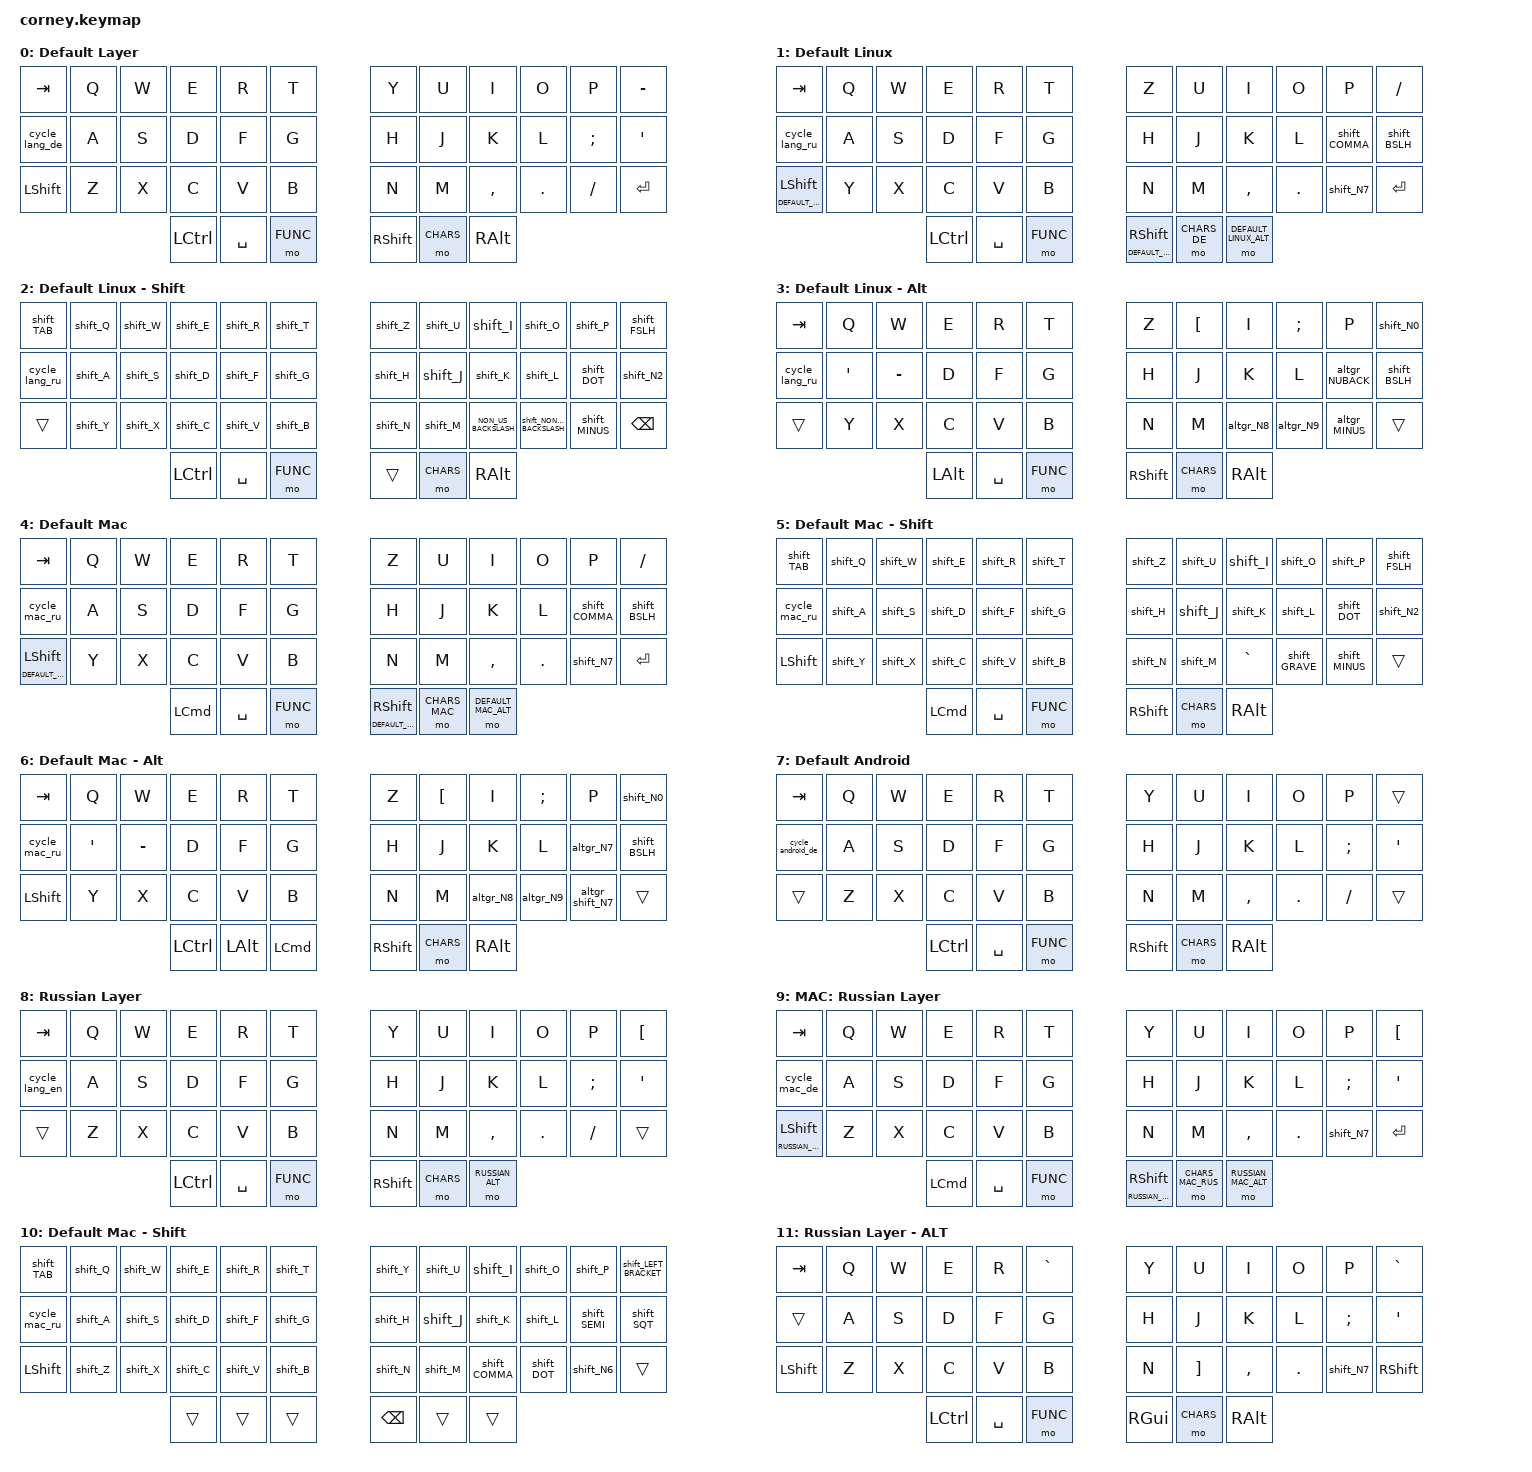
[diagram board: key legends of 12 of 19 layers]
/*
 * Copyright (c) 2020 The ZMK Contributors
 *
 * SPDX-License-Identifier: MIT
 */

#include <behaviors.dtsi>
#include <dt-bindings/zmk/keys.h>
#include <dt-bindings/zmk/bt.h>
#include <dt-bindings/zmk/ext_power.h>
#include <dt-bindings/zmk/pointing.h>
#include <dt-bindings/zmk/mouse.h>

#include "corney_macros.dtsi"


/ {
        behaviors {
                shift_mo: shift_momentary_layer {
                        compatible = "zmk,behavior-hold-tap";
                        #binding-cells = <2>;
                        flavor = "hold-preferred";
                        tapping-term-ms = <200>;
                        bindings = <&mo>, <&kp>;
                };
        };

        keymap {
                compatible = "zmk,keymap";

                default_layer {
                        display-name = "Default Layer";
// -----------------------------------------------------------------------------------------
// |  TAB |  Q  |  W  |  E  |  R  |  T  |   |  Y  |  U   |  I  |  O  |  P  | BSPC |
// | LANG |  A  |  S  |  D  |  F  |  G  |   |  H  |  J   |  K  |  L  |  ;  |  '   |
// | SHFT |  Z  |  X  |  C  |  V  |  B  |   |  N  |  M   |  ,  |  .  |  /  | SHFT |
//                    | CTRL| SPACE  | LWR  |   | SPACE| RSE  | ALT |
                        bindings = <
   &kp TAB        &kp Q &kp W &kp E &kp R &kp T           &kp Y &kp U  &kp I     &kp O     &kp P    &kp MINUS
   &cycle_lang_de &kp A &kp S &kp D &kp F &kp G           &kp H &kp J  &kp K     &kp L     &kp SEMI &kp SQT
   &kp LSHFT      &kp Z &kp X &kp C &kp V &kp B           &kp N &kp M  &kp COMMA &kp DOT   &kp FSLH &kp RET
                      &kp LCTRL  &kp SPACE &mo FUNC       &kp RSHFT &mo CHARS &kp RALT 
                        >;
                };
                

                default_linux {
                        display-name = "Default Linux";
// -----------------------------------------------------------------------------------------
// |  TAB |  q  |  w  |  e  |  r  |  t  |   |  y  |  u   |  i  |  o  |  p  | -     |
// | LANG |  a  |  s  |  d  |  f  |  g  |   |  h  |  j   |  k  |  l  |  ;  |  '    |
// | SHFT |  z  |  x  |  c  |  v  |  b  |   |  n  |  m   |  ,  |  .  |  /  | SHFT  |
//                    | CTRL| SPACE | LWR  |   | SPACE| RSE  | ALT |
                        bindings = <
   &kp TAB                 &kp Q &kp W &kp E     &kp R     &kp T           &kp Z      &kp U        &kp I     &kp O   &kp P         &kp FSLH
   &cycle_lang_ru          &kp A &kp S &kp D     &kp F     &kp G           &kp H      &kp J        &kp K     &kp L   &shift_COMMA  &shift_BSLH
   &shift_mo DEFAULT_LINUX_SHIFT LSHFT &kp Y &kp X &kp C &kp V &kp B       &kp N      &kp M        &kp COMMA &kp DOT &shift_N7 &kp RET 
                                       &kp LCTRL &kp SPACE &mo FUNC        &shift_mo DEFAULT_LINUX_SHIFT RSHFT   &mo CHARS_DE &mo DEFAULT_LINUX_ALT 
                        >;
                };

                default_linux_shift {
                        display-name = "Default Linux - Shift";
// -----------------------------------------------------------------------------------------
// |  TAB |  Q  |  W  |  E  |  R  |  T  |   |  Y  |  U   |  I  |  O  |  P  | _     |
// | LANG |  A  |  S  |  D  |  F  |  G  |   |  H  |  J   |  K  |  L  |  ;  |  "    |
// |      |  Z  |  X  |  C  |  V  |  B  |   |  N  |  M   |  <  |  >  |  ?  |       |
//                    | CTRL| SPACE | LWR |   | SPACE| RSE  | ALT |
                        bindings = <
   &shift_TAB     &shift_Q &shift_W &shift_E  &shift_R &shift_T     &shift_Z  &shift_U  &shift_I             &shift_O                &shift_P     &shift_FSLH
   &cycle_lang_ru &shift_A &shift_S &shift_D  &shift_F &shift_G     &shift_H  &shift_J  &shift_K             &shift_L                &shift_DOT   &shift_N2
   &trans         &shift_Y &shift_X &shift_C  &shift_V &shift_B     &shift_N  &shift_M  &kp NON_US_BACKSLASH &shift_NON_US_BACKSLASH &shift_MINUS &kp BSPC
                                    &kp LCTRL &kp SPACE &mo FUNC    &trans  &mo CHARS &kp RALT 
                        >;
                };

                default_linux_alt {
                        display-name = "Default Linux - Alt";
// -----------------------------------------------------------------------------------------
// |  TAB |  Q  |  W  |  E  |  R  |  T  |   |  Y  |  Ü   |  I  |  Ö  |  P  |  =   |
// | LANG |  Ä  |  ß  |  D  |  F  |  G  |   |  H  |  J   |  K  |  L  | "|" |  '   |
// | SHFT |  Z  |  X  |  C  |  V  |  B  |   |  N  |  M   |  ,  |  .  |  \  | SHFT |
//                    | LALT| SPACE | LWR |   | SPACE| RSE  | ALT |
                        bindings = <
   &kp TAB        &kp Q &kp W &kp E &kp R &kp T           &kp Z &kp LBKT &kp I     &kp  SEMI &kp P         &shift_N0
   &cycle_lang_ru &kp SQT &kp MINUS &kp D &kp F &kp G     &kp H &kp J    &kp K     &kp L     &altgr_NUBACK &shift_BSLH
   &trans         &kp Y &kp X &kp C &kp V &kp B           &kp N &kp M    &altgr_N8 &altgr_N9 &altgr_MINUS  &trans
                     &kp LALT &kp SPACE &mo FUNC          &kp RSHFT       &mo CHARS &kp RALT 
                        >;
                };

                default_mac {
                        display-name = "Default Mac";
// -----------------------------------------------------------------------------------------
// |  TAB |  q  |  w  |  e  |  r  |  t  |   |  y  |  u   |  i  |  o  |  p  | -     |
// | LANG |  a  |  s  |  d  |  f  |  g  |   |  h  |  j   |  k  |  l  |  ;  |  '    |
// | SHFT |  z  |  x  |  c  |  v  |  b  |   |  n  |  m   |  ,  |  .  |  /  | SHFT  |
//                    | CTRL| SPACE | LWR |   | SPACE| RSE  | ALT |
                        bindings = <
   &kp TAB                &kp Q &kp W &kp E     &kp R    &kp T           &kp Z      &kp U         &kp I     &kp O   &kp P         &kp FSLH
   &cycle_mac_ru          &kp A &kp S &kp D     &kp F    &kp G           &kp H      &kp J         &kp K     &kp L   &shift_COMMA  &shift_BSLH
   &shift_mo DEFAULT_MAC_SHIFT LSHFT  &kp Y &kp X &kp C     &kp V    &kp B          &kp N      &kp M         &kp COMMA &kp DOT &shift_N7 &kp RET
                                       &kp LEFT_COMMAND &kp SPACE &mo FUNC          &shift_mo DEFAULT_MAC_SHIFT RSHFT &mo CHARS_MAC &mo DEFAULT_MAC_ALT 
                        >;
                };

                default_mac_shift {
                        display-name = "Default Mac - Shift";
// -----------------------------------------------------------------------------------------
// |  TAB |  Q  |  W  |  E  |  R  |  T  |   |  Y  |  U   |  I  |  O  |  P  | _   |
// | LANG |  A  |  S  |  D  |  F  |  G  |   |  H  |  J   |  K  |  L  |  ;  |  "  |
// |      |  Z  |  X  |  C  |  V  |  B  |   |  N  |  M   |  <  |  >  |  ?  |     |
//                    | CTRL| SPACE | LWR |   | SPACE| RSE  | ALT |
                        bindings = <
   &shift_TAB     &shift_Q &shift_W &shift_E  &shift_R &shift_T     &shift_Z  &shift_U  &shift_I  &shift_O     &shift_P     &shift_FSLH
   &cycle_mac_ru  &shift_A &shift_S &shift_D  &shift_F &shift_G     &shift_H  &shift_J  &shift_K  &shift_L     &shift_DOT   &shift_N2
   &kp LSHFT      &shift_Y &shift_X &shift_C  &shift_V &shift_B     &shift_N  &shift_M  &kp GRAVE &shift_GRAVE &shift_MINUS &trans
                                &kp LEFT_COMMAND &kp SPACE &mo FUNC    &kp RSHFT &mo CHARS &kp RALT 
                        >;
                };

                default_mac_alt {
                        display-name = "Default Mac - Alt";
// -----------------------------------------------------------------------------------------
// |  TAB |  Q  |  W  |  E  |  R  |  T  |   |  Y  |  Ü   |  I  |  Ö  |  P  | =    |
// | LANG |  Ä  |  ß  |  D  |  F  |  G  |   |  H  |  J   |  K  |  L  | "|" |  '   |
// | SHFT |  Z  |  X  |  C  |  V  |  B  |   |  N  |  M   |  ,  |  .  |  \  | SHFT |
//                    | CTRL| SPACE | LWR |   | SPACE| RSE  | ALT |
                        bindings = <
   &kp TAB       &kp Q   &kp W     &kp E     &kp R    &kp T            &kp Z      &kp LBKT  &kp I     &kp  SEMI &kp P           &shift_N0
   &cycle_mac_ru &kp SQT &kp MINUS &kp D     &kp F    &kp G            &kp H      &kp J     &kp K     &kp L     &altgr_N7       &shift_BSLH
   &kp LSHFT     &kp Y   &kp X     &kp C     &kp V    &kp B            &kp N      &kp M     &altgr_N8 &altgr_N9 &altgr_shift_N7 &trans
                                   &kp LCTRL &kp LALT &kp LEFT_COMMAND &kp RSHFT  &mo CHARS &kp RALT 
                        >;
                };

                default_android {
                        display-name = "Default Android";
// -----------------------------------------------------------------------------------------
// |  TAB |  Q  |  W  |  E  |  R  |  T  |   |  Y  |  U   |  I  |  O  |  P  | BSPC  |
// | LANG |  A  |  S  |  D  |  F  |  G  |   |  H  |  J   |  K  |  L  |  ;  |  '    |
// | SHFT |  Z  |  X  |  C  |  V  |  B  |   |  N  |  M   |  ,  |  .  |  /  | SHFT  |
//                    | CTRL| SPACE | LWR |   | SPACE| RSE  | ALT |
                        bindings = <
   &kp TAB   &kp Q &kp W &kp E &kp R &kp T           &kp Y &kp U  &kp I     &kp O     &kp P    &trans
   &cycle_android_de  &kp A &kp S &kp D &kp F &kp G  &kp H &kp J  &kp K     &kp L     &kp SEMI &kp SQT
   &trans    &kp Z &kp X &kp C &kp V &kp B           &kp N &kp M  &kp COMMA &kp DOT   &kp FSLH &trans
                     &kp LCTRL &kp SPACE &mo FUNC    &kp RSHFT  &mo CHARS &kp RALT 
                        >;
                };

                russian {
                        display-name = "Russian Layer";
// -----------------------------------------------------------------------------------------
// |  TAB |  й  |  ц  |  у  |  к  |  е  |   |  н  |  г   |  ш  |  щ  |  з  |  х   |
// | LANG |  ф  |  ы  |  в  |  а  |  п  |   |  р  |  о   |  л  |  д  |  ж  |  э   |
// | SHFT |  я  |  ч  |  с  |  м  |  и  |   |  т  |  ь   |  б  |  ю  |  .  | SHFT |
//                    | CTRL| SPACE | LWR |   | SPACE| RSE  | ALT |
                        bindings = <
   &kp TAB        &kp Q &kp W &kp E &kp R &kp T           &kp Y &kp U  &kp I     &kp O     &kp P    &kp LEFT_BRACKET
   &cycle_lang_en &kp A &kp S &kp D &kp F &kp G           &kp H &kp J  &kp K     &kp L     &kp SEMI &kp SQT
   &trans         &kp Z &kp X &kp C &kp V &kp B           &kp N &kp M  &kp COMMA &kp DOT   &kp FSLH &trans
                     &kp LCTRL &kp SPACE &mo FUNC         &kp RSHFT &mo CHARS &mo RUSSIAN_ALT 
                        >;
                };                

                russian_mac {
                        display-name = "MAC: Russian Layer";
// -----------------------------------------------------------------------------------------
// |  TAB |  й  |  ц  |  у  |  к  |  е  |   |  н  |  г   |  ш  |  щ  |  з  |  з   |
// | LANG |  ф  |  ы  |  в  |  а  |  а  |   |  р  |  о   |  л  |  д  |  ж  |  э   |
// | SHFT |  я  |  ч  |  с  |  м  |  и  |   |  т  |  ь   |  б  |  ю  |  .  | SHFT |
//                    | CTRL| SPACE | LWR |   | SPACE| RSE  | ALT |
                        bindings = <
   &kp TAB               &kp Q &kp W &kp E     &kp R    &kp T            &kp Y      &kp U             &kp I     &kp O     &kp P     &kp LEFT_BRACKET
   &cycle_mac_de         &kp A &kp S &kp D     &kp F    &kp G            &kp H      &kp J             &kp K     &kp L     &kp SEMI  &kp SQT
   &shift_mo RUSSIAN_MAC_SHIFT LSHFT &kp Z &kp X &kp C     &kp V    &kp B            &kp N      &kp M             &kp COMMA &kp DOT   &shift_N7 &kp RET
                             &kp LEFT_COMMAND &kp SPACE &mo FUNC         &shift_mo RUSSIAN_MAC_SHIFT RSHFT    &mo CHARS_MAC_RUS &mo RUSSIAN_MAC_ALT 
                        >;
                };

                russian_mac_shift {
                        display-name = "Default Mac - Shift";
// -----------------------------------------------------------------------------------------
// |  TAB |  Й  |  Ц  |  У  |  К  |  Ё  |   |  Н  |  Г   |  Ш  |  Щ  |  З  |  Х   |
// | LANG |  Ф  |  Ы  |  В  |  А  |  П  |   |  Р  |  О   |  Л  |  Д  |  Ж  |  Э  |
// |      |  Я  |  Ч  |  С  |  М  |  И  |   |  Т  |  Ь   |  Б  |  Ю  |  ,  |     |
//                    | CTRL| SPACE | LWR |   | SPACE| RSE  | ALT |
                        bindings = <
   &shift_TAB     &shift_Q &shift_W &shift_E  &shift_R &shift_T     &shift_Y  &shift_U  &shift_I     &shift_O     &shift_P     &shift_LEFT_BRACKET
   &cycle_mac_ru  &shift_A &shift_S &shift_D  &shift_F &shift_G     &shift_H  &shift_J  &shift_K     &shift_L     &shift_SEMI  &shift_SQT
   &kp LSHFT      &shift_Z &shift_X &shift_C  &shift_V &shift_B     &shift_N  &shift_M  &shift_COMMA &shift_DOT   &shift_N6    &trans
                                    &trans    &trans   &trans       &kp BSPC  &trans    &trans 
                        >;
                };                

                russia_altgr {
                        display-name = "Russian Layer - ALT";
// -----------------------------------------------------------------------------------------
// |  TAB |  Й  |  Ц  |  У  |  К  |  Ё  |   |  Н  |  Г   |  Ш  |  Щ  |  З  |  Х   |
// | LANG |  A  |  S  |  D  |  F  |  G  |   |  Р  |  О   |  Л  |  Д  |  Ж  |  Э   |
// | SHFT |  Z  |  X  |  C  |  V  |  B  |   |  Т  |  Ъ   |  Б  |  Ю  |  ,  | SHFT |
//                    | CTRL| SPACE | LWR |   | SPACE| RSE  | ALT |
                        bindings = <
   &kp TAB   &kp Q &kp W &kp E &kp R &kp GRAVE             &kp Y &kp U  &kp I      &kp O     &kp P    &kp GRAVE
   &trans    &kp A &kp S &kp D &kp F &kp G                 &kp H &kp J  &kp K      &kp L     &kp SEMI &kp SQT
   &kp LSHFT &kp Z &kp X &kp C &kp V &kp B                 &kp N &kp RIGHT_BRACKET &kp COMMA &kp DOT  &shift_N7 &kp RSHFT
                     &kp LCTRL &kp SPACE &mo FUNC          &kp RGUI  &mo CHARS &kp RALT 
                        >;
                };

                russia_mac_altgr {
                        display-name = "MAC: Russian Layer - ALT";
// -----------------------------------------------------------------------------------------
// |  TAB |  Й  |  Ц  |  У  |  К  |  Ё  |   |  Н  |  Г   |  Ш  |  Щ  |  З  |  Х   |
// | LANG |  A  |  S  |  D  |  F  |  G  |   |  Р  |  О   |  Л  |  Д  |  Ж  |  Э   |
// | SHFT |  Z  |  X  |  C  |  V  |  B  |   |  Т  |  Ъ   |  Б  |  Ю  |  ,  | SHFT |
//                    | CTRL| SPACE | LWR |   | SPACE| RSE  | ALT |
                        bindings = <
   &kp TAB   &kp Q &kp W &kp E &kp R &kp BACKSLASH         &kp Y     &kp U              &kp I     &kp O   &kp P       &kp GRAVE
   &trans    &kp A &kp S &kp D &kp F &kp G                 &kp H     &kp J              &kp K     &kp L   &kp SEMI    &kp SQT
   &kp LSHFT &kp Z &kp X &kp C &kp V &kp B                 &kp N     &kp RIGHT_BRACKET  &kp COMMA &kp DOT &shift_FSLH &trans
                     &kp LCTRL &kp LALT &kp LEFT_COMMAND   &kp RSHFT &mo CHARS          &kp RALT 
                        >;
                };                


                functional_layer {
                        display-name = "Functional Layer";
// -----------------------------------------------------------------------------------------
// |  ~   |  1  |  2  |  3  |  4  |  5  |   |  6  |  7  |  8  |  9  |  0  | BSPC |
// | F1   | F2  | F3  | F4  | F5  | F6  |   | F7  | F8  |  F9 | F10 | F11 |  F12 |
// | BTCLR| BT1 | BT2 | BT3 | BT4 | BT5 |   |     |     |     |     |     |      |
//                    | GUI |     |     |   |     |     | ALT |
                        bindings = <
   &kp ESC    &kp N1        &kp N2       &kp N3       &kp N4       &kp N5         &kp N6   &kp N7   &kp N8 &kp N9  &kp N0  &trans
   &kp F1     &kp F2        &kp F3       &kp F4       &kp F5       &kp F6         &kp F7   &kp F8   &kp F9 &kp F10 &kp F11 &kp F12
   &bt BT_CLR &to_linux     &to_mac      &to_mac2     &to_mac3     &to_android    &trans   &trans   &trans &trans  &trans  &trans
                                         &kp LGUI     &trans       &trans         &kp DEL  &kp RALT &kp RCTRL
                        >;
                };

                chars_layer {
                        display-name = "Characters and Navigation";
// -----------------------------------------------------------------------------------------
// | TAB  |  !  |  @  |  #  |  $  |  %  |   |  ^  |  &  |  *  |  (  |  )  |  ~   |
// |  \   |  -  |  +  |  =  |  [  |  ]  |   |  ←  |  ↓  |  ↑  |  →  | "|" |  `   |
// | SHFT |     |     |  €  |  {  |  }  |   |Home | PgDn|PgUp | End | Ins | Del  |
//                    | GUI |     |     |   |     |     | ALT |
                        bindings = <
   &kp TAB     &kp EXCL  &kp AT    &kp HASH  &kp DLLR   &kp PRCNT  &kp CARET &kp AMPS  &kp ASTRK &kp LPAR  &kp RPAR   &kp TILDE
   &kp BSLH    &kp MINUS &kp PLUS  &kp EQUAL &kp LBKT   &kp RBKT   &kp LEFT  &kp DOWN  &kp UP    &kp RIGHT &kp PIPE   &kp GRAVE
   &kp LSHFT   &trans    &trans    &altgr_e  &kp LBRC   &kp RBRC   &kp HOME  &kp PG_DN &kp PG_UP &kp END   &kp INSERT &kp DELETE
                             &kp LALT &trans   &trans   &trans   &trans    &kp RALT
                        >;
                };


                chars_layer_de {
                        display-name = "Characters and Navigation";
// -----------------------------------------------------------------------------------------
// | TAB  |  !  |  @  |  #  |  $  |  %  |   |  ^  |  &  |  *  |  (  |  )  |  ~   |
// |  \   |  -  |  +  |  =  |  [  |  ]  |   |  ←  |  ↓  |  ↑  |  →  | "|" |  `   |
// | SHFT |     |     |  €  |  {  |  }  |   |Home | PgDn|PgUp | End | Ins | Del  |
//                    | ALT |     | GUI |   |    |     | ALT |
                        bindings = <
   &kp TAB      &kp EXCL  &altgr_q_for_at &kp BACKSLASH &kp DLLR  &kp PRCNT      &kp GRAVE  &kp CARET &shift_RBKT &kp ASTRK  &kp LPAR      &altgr_RBKT
   &altgr_MINUS &kp FSLH  &kp RBKT        &shift_N0     &altgr_N8 &altgr_N9      &kp LEFT   &kp DOWN  &kp UP    &kp RIGHT    &altgr_NUBACK &shift_EQUAL
   &kp LSHFT    &trans    &trans          &altgr_e      &altgr_N7 &altgr_N0      &kp HOME   &kp PG_DN &kp PG_UP   &kp END    &kp INSERT    &kp DELETE
                                          &kp LCTRL     &kp LGUI  &kp LALT      &trans     &trans    &kp RALT
                        >;
                };

                chars_layer_mac {
                        display-name = "MAC: Characters and Navigation";
// -----------------------------------------------------------------------------------------
// | TAB  |  !  |  @  |  #  |  $  |  %  |   |  ^  |  &  |  *  |  (  |  )  |  ~   |
// |      |  -  |  +  |  =  |  [  |  ]  |   |  ←  |  ↓  |  ↑  |  →  | "|" |  `   |
// | SHFT |     |     |  €  |  {  |  }  |   |Home | PgDn|PgUp | End | Ins | Del  |
//                    | GUI |     |     |   |    |     | ALT |
                        bindings = <
   &kp TAB      &kp EXCL  &altgr_l_for_at &kp BACKSLASH &kp DLLR  &kp PRCNT                &kp NON_US_BACKSLASH &kp CARET &shift_RBKT &kp ASTRK     &kp LPAR      &altgr_N
   &altgr_shift_N7 &kp FSLH  &kp RBKT     &shift_N0     &altgr_N5 &altgr_N6                &kp LEFT             &kp DOWN  &kp UP      &kp RIGHT     &altgr_N7     &shift_EQUAL
   &kp LSHFT    &trans    &trans          &altgr_e      &altgr_N8 &altgr_N9                &kp HOME             &kp PG_DN &kp PG_UP   &kp END       &kp INSERT    &kp DELETE
                                          &kp LCTRL     &kp LALT  &kp LEFT_COMMAND     &trans               &trans    &kp RALT
                        >;
                };                

                chars_layer_mac_rus {
                        display-name = "MAC: Characters and Navigation Russian";
// -----------------------------------------------------------------------------------------
// | TAB  |  !  |  @  |  #  |  $  |  %  |   |  ^  |  &  |  *  |  (  |  )  |  ~   |
// |      |  -  |  +  |  =  |  [  |  ]  |   |  ←  |  ↓  |  ↑  |  →  | "|" |  `   |
// | SHFT |     |     |  €  |  {  |  }  |   |Home | PgDn|PgUp | End | Ins | Del  |
//                    | GUI |     |     |   |    |     | ALT |
                        bindings = <
   &kp TAB         &kp EXCL  &altgr_l_for_at &kp BACKSLASH &kp DLLR  &kp PRCNT                &kp NON_US_BACKSLASH &kp CARET &shift_RBKT &kp ASTRK     &kp LPAR      &altgr_N
   &altgr_shift_N7 &kp MINUS &shift_EQUAL    &kp EQUAL     &altgr_N5 &altgr_N6                &kp LEFT             &kp DOWN  &kp UP      &kp RIGHT     &altgr_N7     &shift_EQUAL
   &kp LSHFT       &trans    &trans          &altgr_e      &altgr_N8 &altgr_N9                &kp HOME             &kp PG_DN &kp PG_UP   &kp END       &kp INSERT    &kp DELETE
                                             &kp LCTRL     &kp LALT  &kp LEFT_COMMAND         &trans               &trans    &kp RALT
                        >;
                };  

                mouse_layer {
                        display-name = "Mouse Layer";
// -----------------------------------------------------------------------------------------
// |NumLock|  /  |  7  |  8  |  9  |  *  |   |     |     |     |     |     |      |
// |       |  ,  |  4  |  5  |  6  |  -  |   | M←  | M↓  | M↑  | M→  |     |      |
// |       |  0  |  1  |  2  |  3  |  +  |   | s↓  | LC  | RC  | s↑  |     |      |
//                     | LC  | RC  |  ⏎  |   |     |     | ALT |
                        bindings = <
   &kp KP_NUM &kp KP_DIVIDE &kp KP_N7 &kp KP_N8 &kp KP_N9    &kp KP_MULTIPLY   &trans           &trans         &trans       &trans          &trans &trans
   &trans     &kp KP_DOT    &kp KP_N4 &kp KP_N5 &kp KP_N6    &kp KP_MINUS      &mmv MOVE_LEFT   &mmv MOVE_DOWN &mmv MOVE_UP &mmv MOVE_RIGHT &trans &trans
   &kp LSHFT  &kp KP_N0     &kp KP_N1 &kp KP_N2 &kp KP_N3    &kp KP_PLUS       &msc SCRL_DOWN   &mkp LCLK      &mkp RCLK    &msc SCRL_UP    &trans &kp RSHFT  
                            &mkp LCLK &mkp RCLK  &kp KP_ENTER                     &mkp LCLK        &trans         &kp RALT
                        >;
                };


        };

        
};
